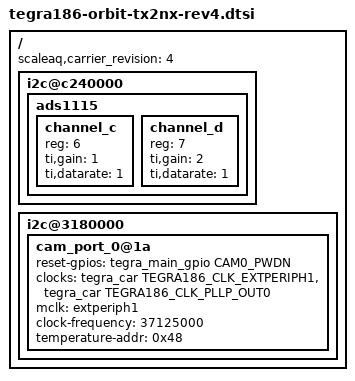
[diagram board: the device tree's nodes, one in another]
#include "tegra186-scaleaq-common.dtsi"

/ {
	scaleaq,carrier_revision = "4";

	i2c@c240000 {
		ads1115 {
			channel_c: channel_c {
				/* hardware revision ADC */
				reg = <6>;
				ti,gain = <1>;
				ti,datarate = <1>;
			};

			channel_d: channel_d {
				/* PoE voltage ADC */
				reg = <7>;
				ti,gain = <2>;
				ti,datarate = <1>;
			};
		};
	};

	/delete-node/ cam_i2cmux;

	i2c@3180000 {
		#address-cells = <1>;
		#size-cells = <0>;
		cam_port_0@1a {
			reset-gpios = <&tegra_main_gpio CAM0_PWDN GPIO_ACTIVE_HIGH>;

			clocks = <&tegra_car TEGRA186_CLK_EXTPERIPH1>, <&tegra_car TEGRA186_CLK_PLLP_OUT0>;
				clock-names = "extperiph1", "pllp_grtba";
				mclk = "extperiph1";
				clock-frequency = <37125000>;

			temperature-addr = <0x48>;
		};
	};
};
